# TestDevice register map
Vendor: TestVendor; File version: 1.0
Minimal test SVD for unit tests
Registers are 32-bit, read-write, reset 0x0 unless marked. A register's access mark holds for its fields unless they carry their own. Offsets are from the block's base; lines under a group give offsets from that group; [hi:lo] are bit positions; {n}, {i} and the like mark numbered series; 'fields as' and 'values as' point back to an identical list; <NAME> marks a mode.

## Memory map
0x40008000 TIMER0 — Timer/Counter 0
0x50000000 GPIO — General purpose input/output

## GPIO — General purpose input/output
Base 0x50000000
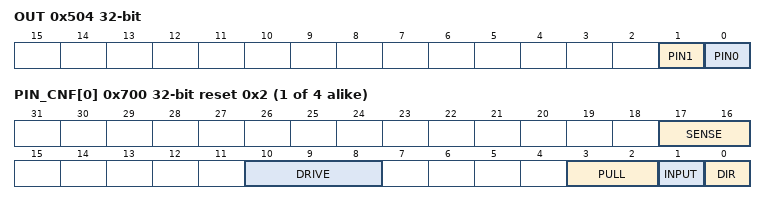
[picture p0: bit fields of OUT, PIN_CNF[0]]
0x504 OUT — Write GPIO port
  [1] PIN1
    0=Low (Pin low); 1=High (Pin high)
  [0] PIN0
    0=Low (Pin low); 1=High (Pin high)
0x508 OUTSET wo — Set individual bits in GPIO port
  [0] PIN0
0x510 IN ro — Read GPIO port
  [0] PIN0
    0=Low (Pin low); 1=High (Pin high)
0x514 DIR — Direction register
  [0] PIN0 — Pin 0 direction
    0=Input; 1=Output
{0x700+4i} PIN_CNF[{i}] (i=0..3) reset 0x2 — Configuration of GPIO pins
  [17:16] SENSE — Pin sensing mechanism
    0=Disabled; 2=High (Sense for high level); 3=Low (Sense for low level)
  [10:8] DRIVE — Drive configuration
    0=S0S1 (Standard 0, standard 1); 1=H0S1 (High drive 0, standard 1); 2=S0H1 (Standard 0, high drive 1); 3=H0H1 (High drive 0, high drive 1)
  [3:2] PULL — Pull configuration
    0=Disabled (No pull); 1=Pull down on pin; 3=Pull up on pin
  [1] INPUT — Connect or disconnect input buffer
    0=Connect input buffer; 1=Disconnect input buffer
  [0] DIR — Pin direction
    0=Input (Configure pin as an input pin); 1=Output (Configure pin as an output pin)

## TIMER0 — Timer/Counter 0
Base 0x40008000
0x504 MODE — Timer mode selection
  [1:0] MODE — Timer mode
    0=Timer mode; 1=Counter mode; 2=Low power counter mode
